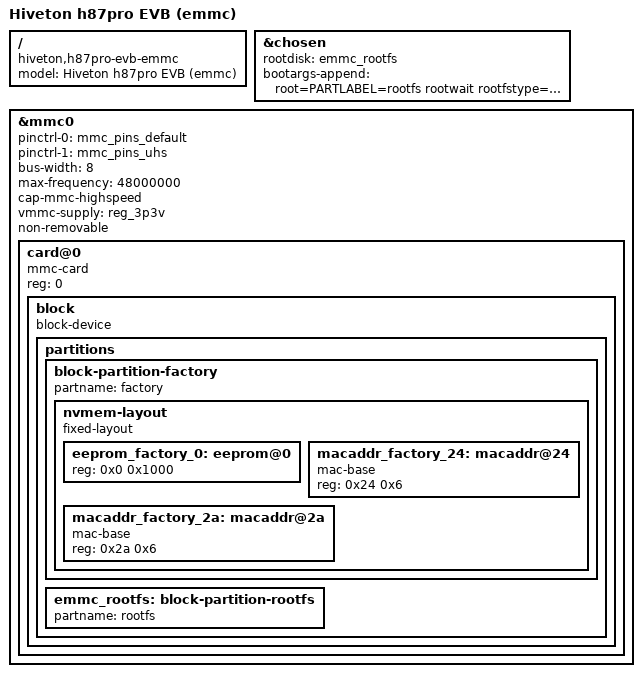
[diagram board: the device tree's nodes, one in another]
// SPDX-License-Identifier: (GPL-2.0 OR MIT)

/dts-v1/;
#include "mt7987a-hiveton-h87pro-evb-base.dts"

/ {
	model = "Hiveton h87pro EVB (emmc)";
	compatible = "hiveton,h87pro-evb-emmc", "mediatek,mt7987";
};

&chosen {
	rootdisk = <&emmc_rootfs>;
	bootargs-append = " root=PARTLABEL=rootfs rootwait rootfstype=squashfs,f2fs";
};

&mmc0 {
	pinctrl-names = "default", "state_uhs";
	pinctrl-0 = <&mmc_pins_default>;
	pinctrl-1 = <&mmc_pins_uhs>;
	bus-width = <8>;
	max-frequency = <48000000>;
	cap-mmc-highspeed;
	vmmc-supply = <&reg_3p3v>;
	non-removable;
	status = "okay";

	card@0 {
		compatible = "mmc-card";
		reg = <0>;

		block {
			compatible = "block-device";

			partitions {
				block-partition-factory {
					partname = "factory";

					nvmem-layout {
						compatible = "fixed-layout";
						#address-cells = <1>;
						#size-cells = <1>;

						eeprom_factory_0: eeprom@0 {
							reg = <0x0 0x1000>;
						};

						macaddr_factory_24: macaddr@24 {
							compatible = "mac-base";
							reg = <0x24 0x6>;
							#nvmem-cell-cells = <1>;
						};

						macaddr_factory_2a: macaddr@2a {
							compatible = "mac-base";
							reg = <0x2a 0x6>;
							#nvmem-cell-cells = <1>;
						};
					};
				};

				emmc_rootfs: block-partition-rootfs {
					partname = "rootfs";
				};
			};
		};
	};
};
